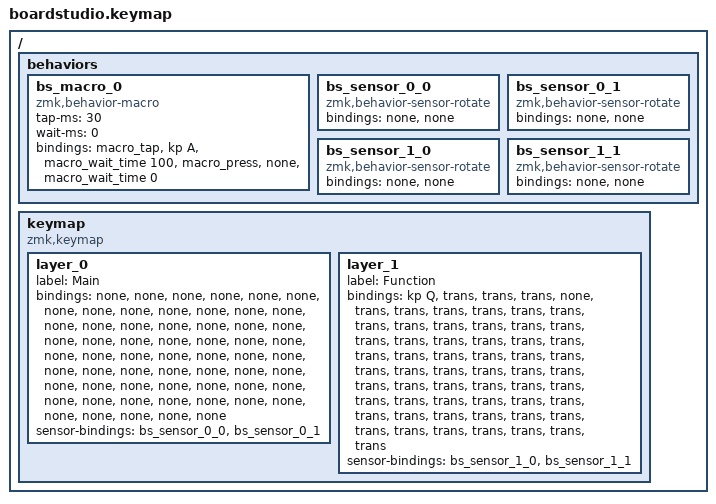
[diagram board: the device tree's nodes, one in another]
#include <behaviors.dtsi>
#include <dt-bindings/zmk/keys.h>
/ { behaviors { bs_macro_0: bs_macro_0 { compatible = "zmk,behavior-macro"; #binding-cells = <0>; tap-ms = <30>; wait-ms = <0>; bindings = <&macro_tap>, <&kp A>, <&macro_wait_time 100>, <&macro_press &none>, <&macro_wait_time 0>; };
bs_sensor_0_0: bs_sensor_0_0 { compatible = "zmk,behavior-sensor-rotate"; #sensor-binding-cells = <0>; bindings = <&none>, <&none>; };
bs_sensor_0_1: bs_sensor_0_1 { compatible = "zmk,behavior-sensor-rotate"; #sensor-binding-cells = <0>; bindings = <&none>, <&none>; };
bs_sensor_1_0: bs_sensor_1_0 { compatible = "zmk,behavior-sensor-rotate"; #sensor-binding-cells = <0>; bindings = <&none>, <&none>; };
bs_sensor_1_1: bs_sensor_1_1 { compatible = "zmk,behavior-sensor-rotate"; #sensor-binding-cells = <0>; bindings = <&none>, <&none>; };
 }; keymap { compatible = "zmk,keymap"; layer_0 { label = "Main"; bindings = <&none &none &none &none &none &none &none &none &none &none &none &none &none &none &none &none &none &none &none &none &none &none &none &none &none &none &none &none &none &none &none &none &none &none &none &none &none &none &none &none &none &none &none &none &none &none &none &none &none &none &none &none &none &none &none &none &none &none &none &none>; sensor-bindings = <&bs_sensor_0_0 &bs_sensor_0_1>; };
layer_1 { label = "Function"; bindings = <&kp Q &trans &trans &trans &none &trans &trans &trans &trans &trans &trans &trans &trans &trans &trans &trans &trans &trans &trans &trans &trans &trans &trans &trans &trans &trans &trans &trans &trans &trans &trans &trans &trans &trans &trans &trans &trans &trans &trans &trans &trans &trans &trans &trans &trans &trans &trans &trans &trans &trans &trans &trans &trans &trans &trans &trans &trans &trans &trans &trans>; sensor-bindings = <&bs_sensor_1_0 &bs_sensor_1_1>; };
 }; };
